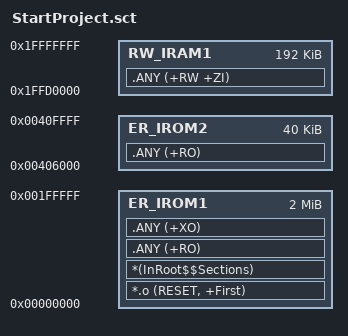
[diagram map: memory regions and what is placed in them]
; *************************************************************
; *** Scatter-Loading Description File generated by uVision ***
; *************************************************************

LR_IROM1 0x00000000 0x00200000  {    ; load region size_region
  ER_IROM1 0x00000000 0x00200000  {  ; load address = execution address
   *.o (RESET, +First)
   *(InRoot$$Sections)
   .ANY (+RO)
   .ANY (+XO)
  }
  RW_IRAM1 0x1FFD0000 0x00030000  {  ; RW data
   .ANY (+RW +ZI)
  }
}

LR_IROM2 0x00406000 0x0000A000  {
  ER_IROM2 0x00406000 0x0000A000  {  ; load address = execution address
   .ANY (+RO)
  }
}
